AUTOSAR XML (schema 4-2-2)
package /AUTOLIV/SoftwareComponents/McuIf
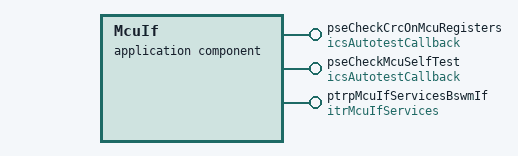
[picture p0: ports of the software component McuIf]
  application sw component type McuIf: category=SWC  # McuIf_AC_Mcu
    provide port pseCheckCrcOnMcuRegisters: server-com-spec{operation=AutotestCallback, queue-length=1}, provided-interface=icsAutotestCallback  # # Architecture Element ID - ARCH_SW_McuIf_pseCheckCrcOnMcuRegisters_McuIf_CheckMcuCrcRegisterStatus # Description - The auto-test shall detect if the MCU PORT, ADC and FTM registers are changed during runtime. # Data Flow ## Inputs ## Outputs - {Autotest Result} - Can be one of the following values: OK, NOK, NOT DECIDED # Linked Runnable - McuIf_CheckMcuCrcRegisterStatus #Traceability FUSA_SM_S32K1XXSM_853 FUSA_SM_S32K1XXSM_852 FUSA_SM_S32K1XXSM_574 FUSA_SM_S32K1XXSM_572 FUSA_SM_S32K1XXSM_570 FUSA_SM_S32K1XXSM_556 DOM_eCS_TF_H_388 DOM_eCS_TF_H_389 DOM_eCS_TF_H_390
    provide port pseCheckMcuSelfTest: server-com-spec{operation=AutotestCallback, queue-length=1}, provided-interface=icsAutotestCallback  # # Architecture Element ID - ARCH_SW_McuIf_pseCheckMcuSelfTest_McuIf_CheckMcuSelfTest # Description - The auto-test shall detect if the MCU is functioning correct - The NXP core library is called to do the actual check # Data Flow ## Inputs ## Outputs - {Autotest Result} - Can be one of the following values: OK, NOK, NOT DECIDED # Linked Runnable - McuIf_CheckMcuSelfTest #Traceability DOM_eCS_TF_H_233, DOM_eCS_TF_H_234, DOM_eCS_TF_H_235
    provide port ptrpMcuIfServicesBswmIf: provided-interface=itrMcuIfServices  # # Architecture Element ID ARCH_SW_McuIf_ptrpMcuIfServicesBswmIf_McuIf_runInit # Description - The McuIf_runInit runnable shall be called in the BswM_OnRunFromWakeup runnable in order to initialize and calculate PORT, ADC and FTM CRC on registers. # Data Flow # Linked Runnable - McuIf_runInit #Traceability
